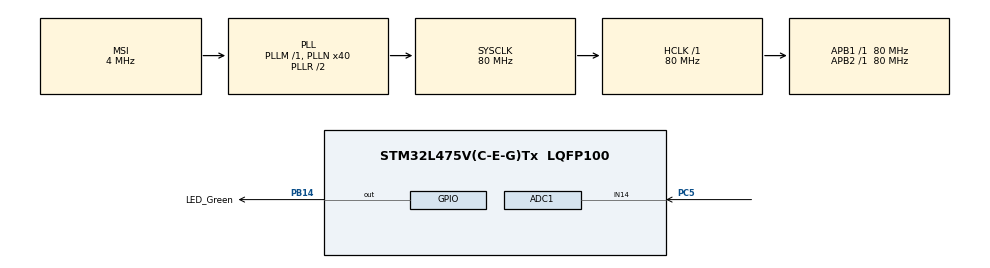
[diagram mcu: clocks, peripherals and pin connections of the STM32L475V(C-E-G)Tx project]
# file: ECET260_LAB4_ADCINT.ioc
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ADC1.Channel-0\#ChannelRegularConversion=ADC_CHANNEL_14
ADC1.NbrOfConversionFlag=1
ADC1.OffsetNumber-0\#ChannelRegularConversion=ADC_OFFSET_NONE
ADC1.Rank-0\#ChannelRegularConversion=1
ADC1.SamplingTime-0\#ChannelRegularConversion=ADC_SAMPLETIME_47CYCLES_5
ADC1.master=1
Mcu.Family=STM32L4
Mcu.Name=STM32L475V(C-E-G)Tx
Mcu.Package=LQFP100
NVIC.ADC1_2_IRQn=true\:0\:0\:false\:false\:true\:true\:true
NVIC.PriorityGroup=NVIC_PRIORITYGROUP_4
PB14.GPIO_Label=LED_Green
PB14.Signal=GPIO_Output
PC5.Signal=ADCx_IN14
ProjectManager.HeapSize=0x200
ProjectManager.StackSize=0x400
ProjectManager.TargetToolchain=TrueSTUDIO
RCC.ADCFreq_Value=32000000
RCC.AHBFreq_Value=80000000
RCC.APB1Freq_Value=80000000
RCC.APB1TimFreq_Value=80000000
RCC.APB2Freq_Value=80000000
RCC.APB2TimFreq_Value=80000000
RCC.CortexFreq_Value=80000000
RCC.HCLKFreq_Value=80000000
RCC.HSE_VALUE=8000000
RCC.HSI_VALUE=16000000
RCC.LSE_VALUE=32768
RCC.MSI_VALUE=4000000
RCC.PLLN=40
RCC.PLLSAI1N=16
RCC.SYSCLKFreq_VALUE=80000000
RCC.SYSCLKSource=RCC_SYSCLKSOURCE_PLLCLK
RCC.USBFreq_Value=32000000
RCC.VCOOutputFreq_Value=160000000
SH.ADCx_IN14.0=ADC1_IN14,IN14-Single-Ended
board=custom

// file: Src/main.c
/* USER CODE BEGIN Header */
/**
  ******************************************************************************
  * @file           : main.c
  * @brief          : Main program body
  ******************************************************************************
  * @attention
  *
  * <h2><center>&copy; Copyright (c) 2019 STMicroelectronics.
  * All rights reserved.</center></h2>
  *
  * This software component is licensed by ST under BSD 3-Clause license,
  * the "License"; You may not use this file except in compliance with the
  * License. You may obtain a copy of the License at:
  *                        opensource.org/licenses/BSD-3-Clause
  *
  ******************************************************************************
  */
/* USER CODE END Header */

#include "main.h"
#include <stdint.h>
#include <stdio.h>

ADC_HandleTypeDef hadc1;

void SystemClock_Config(void);
static void MX_GPIO_Init(void);
static void MX_ADC1_Init(void);

/* USER CODE BEGIN 0
 *
 */
uint32_t LM35Value;
float LM35temp;

/* USER CODE END 0 */

int main(void)
{

  /* MCU Configuration--------------------------------------------------------*/

  /* Reset of all peripherals, Initializes the Flash interface and the Systick. */
  HAL_Init();

  /* Configure the system clock */
  SystemClock_Config();

  /* Initialize all configured peripherals */
  MX_GPIO_Init();
  MX_ADC1_Init();

  /* Infinite loop */
  /* USER CODE BEGIN WHILE */
  while (1)
  {
	  HAL_ADC_Start_IT(&hadc1);
	  HAL_GPIO_TogglePin(LED_Green_GPIO_Port, LED_Green_Pin);

	  	  	 //HAL_GPIO_WritePin(LED_Green_GPIO_Port, LED_Green_Pin, GPIO_PIN_SET);  //Green on
	  HAL_Delay(500);
	  LM35temp = (LM35Value/4095.0)*329.8;  //convert the value to temperature
	 	     //voltage between source and ground = 3.298V
	 	     //12 bit resolution(Hal user manual pg.92)
	 	     //LM35 Datasheet = 10mV/C Scale Degree

	  printf("LM35Value: %lu    LM35temp: %0.1f\n", LM35Value, LM35temp);

  }
  /* USER CODE END 3 */
}

void SystemClock_Config(void)
{
  RCC_OscInitTypeDef RCC_OscInitStruct = {0};
  RCC_ClkInitTypeDef RCC_ClkInitStruct = {0};
  RCC_PeriphCLKInitTypeDef PeriphClkInit = {0};

  /** Initializes the CPU, AHB and APB busses clocks
  */
  RCC_OscInitStruct.OscillatorType = RCC_OSCILLATORTYPE_MSI;
  RCC_OscInitStruct.MSIState = RCC_MSI_ON;
  RCC_OscInitStruct.MSICalibrationValue = 0;
  RCC_OscInitStruct.MSIClockRange = RCC_MSIRANGE_6;
  RCC_OscInitStruct.PLL.PLLState = RCC_PLL_ON;
  RCC_OscInitStruct.PLL.PLLSource = RCC_PLLSOURCE_MSI;
  RCC_OscInitStruct.PLL.PLLM = 1;
  RCC_OscInitStruct.PLL.PLLN = 40;
  RCC_OscInitStruct.PLL.PLLP = RCC_PLLP_DIV7;
  RCC_OscInitStruct.PLL.PLLQ = RCC_PLLQ_DIV2;
  RCC_OscInitStruct.PLL.PLLR = RCC_PLLR_DIV2;
  if (HAL_RCC_OscConfig(&RCC_OscInitStruct) != HAL_OK)
  {
    Error_Handler();
  }
  /** Initializes the CPU, AHB and APB busses clocks
  */
  RCC_ClkInitStruct.ClockType = RCC_CLOCKTYPE_HCLK|RCC_CLOCKTYPE_SYSCLK
                              |RCC_CLOCKTYPE_PCLK1|RCC_CLOCKTYPE_PCLK2;
  RCC_ClkInitStruct.SYSCLKSource = RCC_SYSCLKSOURCE_PLLCLK;
  RCC_ClkInitStruct.AHBCLKDivider = RCC_SYSCLK_DIV1;
  RCC_ClkInitStruct.APB1CLKDivider = RCC_HCLK_DIV1;
  RCC_ClkInitStruct.APB2CLKDivider = RCC_HCLK_DIV1;

  if (HAL_RCC_ClockConfig(&RCC_ClkInitStruct, FLASH_LATENCY_4) != HAL_OK)
  {
    Error_Handler();
  }
  PeriphClkInit.PeriphClockSelection = RCC_PERIPHCLK_ADC;
  PeriphClkInit.AdcClockSelection = RCC_ADCCLKSOURCE_PLLSAI1;
  PeriphClkInit.PLLSAI1.PLLSAI1Source = RCC_PLLSOURCE_MSI;
  PeriphClkInit.PLLSAI1.PLLSAI1M = 1;
  PeriphClkInit.PLLSAI1.PLLSAI1N = 16;
  PeriphClkInit.PLLSAI1.PLLSAI1P = RCC_PLLP_DIV7;
  PeriphClkInit.PLLSAI1.PLLSAI1Q = RCC_PLLQ_DIV2;
  PeriphClkInit.PLLSAI1.PLLSAI1R = RCC_PLLR_DIV2;
  PeriphClkInit.PLLSAI1.PLLSAI1ClockOut = RCC_PLLSAI1_ADC1CLK;
  if (HAL_RCCEx_PeriphCLKConfig(&PeriphClkInit) != HAL_OK)
  {
    Error_Handler();
  }
  /** Configure the main internal regulator output voltage
  */
  if (HAL_PWREx_ControlVoltageScaling(PWR_REGULATOR_VOLTAGE_SCALE1) != HAL_OK)
  {
    Error_Handler();
  }
}

static void MX_ADC1_Init(void)
{

  ADC_MultiModeTypeDef multimode = {0};
  ADC_ChannelConfTypeDef sConfig = {0};

  /** Common config
  */
  hadc1.Instance = ADC1;
  hadc1.Init.ClockPrescaler = ADC_CLOCK_ASYNC_DIV1;
  hadc1.Init.Resolution = ADC_RESOLUTION_12B;
  hadc1.Init.DataAlign = ADC_DATAALIGN_RIGHT;
  hadc1.Init.ScanConvMode = ADC_SCAN_DISABLE;
  hadc1.Init.EOCSelection = ADC_EOC_SINGLE_CONV;
  hadc1.Init.LowPowerAutoWait = DISABLE;
  hadc1.Init.ContinuousConvMode = DISABLE;
  hadc1.Init.NbrOfConversion = 1;
  hadc1.Init.DiscontinuousConvMode = DISABLE;
  hadc1.Init.ExternalTrigConv = ADC_SOFTWARE_START;
  hadc1.Init.ExternalTrigConvEdge = ADC_EXTERNALTRIGCONVEDGE_NONE;
  hadc1.Init.DMAContinuousRequests = DISABLE;
  hadc1.Init.Overrun = ADC_OVR_DATA_PRESERVED;
  hadc1.Init.OversamplingMode = DISABLE;
  if (HAL_ADC_Init(&hadc1) != HAL_OK)
  {
    Error_Handler();
  }
  /** Configure the ADC multi-mode
  */
  multimode.Mode = ADC_MODE_INDEPENDENT;
  if (HAL_ADCEx_MultiModeConfigChannel(&hadc1, &multimode) != HAL_OK)
  {
    Error_Handler();
  }
  /** Configure Regular Channel
  */
  sConfig.Channel = ADC_CHANNEL_14;
  sConfig.Rank = ADC_REGULAR_RANK_1;
  sConfig.SamplingTime = ADC_SAMPLETIME_47CYCLES_5;
  sConfig.SingleDiff = ADC_SINGLE_ENDED;
  sConfig.OffsetNumber = ADC_OFFSET_NONE;
  sConfig.Offset = 0;
  if (HAL_ADC_ConfigChannel(&hadc1, &sConfig) != HAL_OK)
  {
    Error_Handler();
  }

}

static void MX_GPIO_Init(void)
{
  GPIO_InitTypeDef GPIO_InitStruct = {0};

  /* GPIO Ports Clock Enable */
  __HAL_RCC_GPIOC_CLK_ENABLE();
  __HAL_RCC_GPIOB_CLK_ENABLE();

  /*Configure GPIO pin Output Level */
  HAL_GPIO_WritePin(LED_Green_GPIO_Port, LED_Green_Pin, GPIO_PIN_RESET);

  /*Configure GPIO pin : LED_Green_Pin */
  GPIO_InitStruct.Pin = LED_Green_Pin;
  GPIO_InitStruct.Mode = GPIO_MODE_OUTPUT_PP;
  GPIO_InitStruct.Pull = GPIO_NOPULL;
  GPIO_InitStruct.Speed = GPIO_SPEED_FREQ_LOW;
  HAL_GPIO_Init(LED_Green_GPIO_Port, &GPIO_InitStruct);

}

/* USER CODE BEGIN 4 */
int __io_putchar(int ch)
{
	ITM_SendChar(ch);
	return 0;
}

void HAL_ADC_ConvCpltCallback(ADC_HandleTypeDef *hadc1)
{

	LM35Value = HAL_ADC_GetValue(hadc1); // Read the ADC converted value
	    // HAL_Delay(500);  //wait

	    // printf ("LM35Value: %lu     LM35temp: %0.2f\n", LM35Value, LM35temp);

	     //printing it to serial port
	     //turn on PORT 0 while setting up Serial Wire Viewer in debug mode
	    // HAL_ADC_Start_IT(hadc1);
}

/* USER CODE END 4 */

void Error_Handler(void)
{
}

/************************ (C) COPYRIGHT STMicroelectronics *****END OF FILE****/
